# D1H.pdf register map
Vendor: Allwinner; Series: D1H.pdf; File version: 0.1
CPU: XuanTie C906 RISC-V CPU 0, little endian, MPU, FPU, double-precision FPU, 0 interrupt priority bits
Registers are 32-bit, read-write, reset 0x0 unless marked. A register's access mark holds for its fields unless they carry their own. Offsets are from the block's base; [hi:lo] are bit positions; lines under a group give offsets from that group; {n}, {i} and the like mark numbered series.

## DSP_MSGBOX
Base 0x01701000
Same registers: RISC-V_MSGBOX 0x0601F000
{0x20+0x100*i} _N[{i}] (i=0..1) group
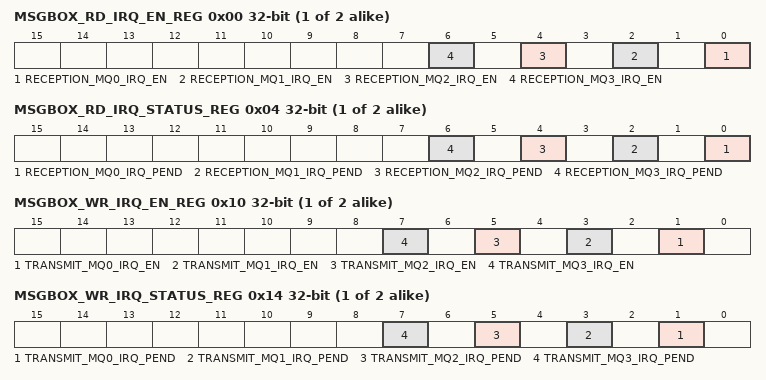
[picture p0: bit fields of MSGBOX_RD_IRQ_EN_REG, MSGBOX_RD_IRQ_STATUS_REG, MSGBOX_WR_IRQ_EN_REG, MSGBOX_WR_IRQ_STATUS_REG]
  0x00 MSGBOX_RD_IRQ_EN_REG — MSGBOX Read IRQ Enable Register
    [2n] RECEPTION_MQ{n}_IRQ_EN (n=0..3) — Reception Channel{n} Interrupt Enable 0: Disable 1: Enable (It notifies user 0 by interrupt when Message Queue {n} received a new message.)
      0=Disable; 1=Enable (It notifies user 0 by interrupt when Message Queue {n} received a new message.)
  0x04 MSGBOX_RD_IRQ_STATUS_REG — MSGBOX Read IRQ Status Register
    [2n] RECEPTION_MQ{n}_IRQ_PEND write-1-clears (n=0..3) — 0: No effect 1: Pending. This bit will be pending for user 0 when Message Queue {n} received a new message. Setting 1 to this bit clears it.
      0=No_effect; 1=Pending. This bit will be pending for user 0 when Message Queue {n} received a new message. Setting 1 to this bit clears it.
  0x10 MSGBOX_WR_IRQ_EN_REG — MSGBOX Write IRQ Enable Register
    [2n+1] TRANSMIT_MQ{n}_IRQ_EN (n=0..3) — 0: Disable 1: Enable (It notifies user 1 by interrupt when Message Queue {n} empty level reaches the configured threshold.)
      0=Disable; 1=Enable (It notifies user 1 by interrupt when Message Queue {n} empty level reaches the configured threshold.)
  0x14 MSGBOX_WR_IRQ_STATUS_REG — MSGBOX Write IRQ Status Register
    [2n+1] TRANSMIT_MQ{n}_IRQ_PEND write-1-clears (n=0..3) — 0: No effect 1: Pending. This bit will be pending for user 1 when Message Queue {n} empty level reaches the configured threshold. Setting 1 to this bit clears it.
      0=No_effect; 1=Pending. This bit will be pending for user 1 when Message Queue {n} empty level reaches the configured threshold. Setting 1 to this bit clears it.
{0x50+0x100*i} _NP[{i}] (i=0..1) group
  {0x0+4j} MSGBOX_FIFO_STATUS_REG[{j}] (j=0..3) — (N=0–1)(P=0–3) MSGBOX FIFO Status Register
    [0] FIFO_NOT_AVA_FLAG ro — FIFO is not available flag 0: The Message FIFO queue empty level reaches the configured threshold 1: The Message FIFO queue empty level does not reach the configured threshold This FIFO status register has the status related to the message queue.
      0=Message_FIFO_queue_empty_level_reaches (The Message FIFO queue empty level reaches the configured threshold); 1=Message_FIFO_queue_empty_level_does (The Message FIFO queue empty level does not reach the configured threshold This FIFO status register has the status related to the message queue.)
  {0x10+4j} MSGBOX_MSG_STATUS_REG[{j}] (j=0..3) — (N=0–1)(P=0–3) MSGBOX Message Status Register
    [3:0] MSG_NUM ro — Message Number Number of unread messages in the message queue. Here, limited to eight messages per message queue. 0000: There is no message in the message FIFO queue. 0001: There is 1 message in the message FIFO queue. 0010: There are 2 messages in the message FIFO queue. 0011: There are 3 messages in the message FIFO queue. 0100: There are 4 messages in the message FIFO queue. 0101: There are 5 messages in the message FIFO queue. 0110: There are 6 messages in the message FIFO queue. 0111: There are 7 messages in the message FIFO queue. 1000: There are 8 messages in the message FIFO queue. 1001~1111:/
      0=no_message (There is no message in the message FIFO queue.); 1=There is 1 message in the message FIFO queue; {v}=There are {v} messages in the message FIFO queue (v=2..7); 8=There are 8 messages in the message FIFO queue. 1001~1111:/
  {0x20+4j} MSGBOX_MSG_REG[{j}] (j=0..3) — (N=0–1)(P=0–3) MSGBOX Message Queue Register
    [31:0] MSG_QUE — The message register stores the next to be read message of the message FIFO queue.
  {0x30+4j} MSGBOX_WR_INT_THRESHOLD_REG[{j}] (j=0..3) — MSGBOX_WR_INT_THRESHOLD_REG[{j}]
    [1:0] MSG_WR_INT_THRESHOLD_CFG — Configure the FIFO empty level to trigger the write interrupt for user1 00: 1 01: 2 10: 4 11: 8
      0=_1; 1=_2; 2=_4; 3=_8
